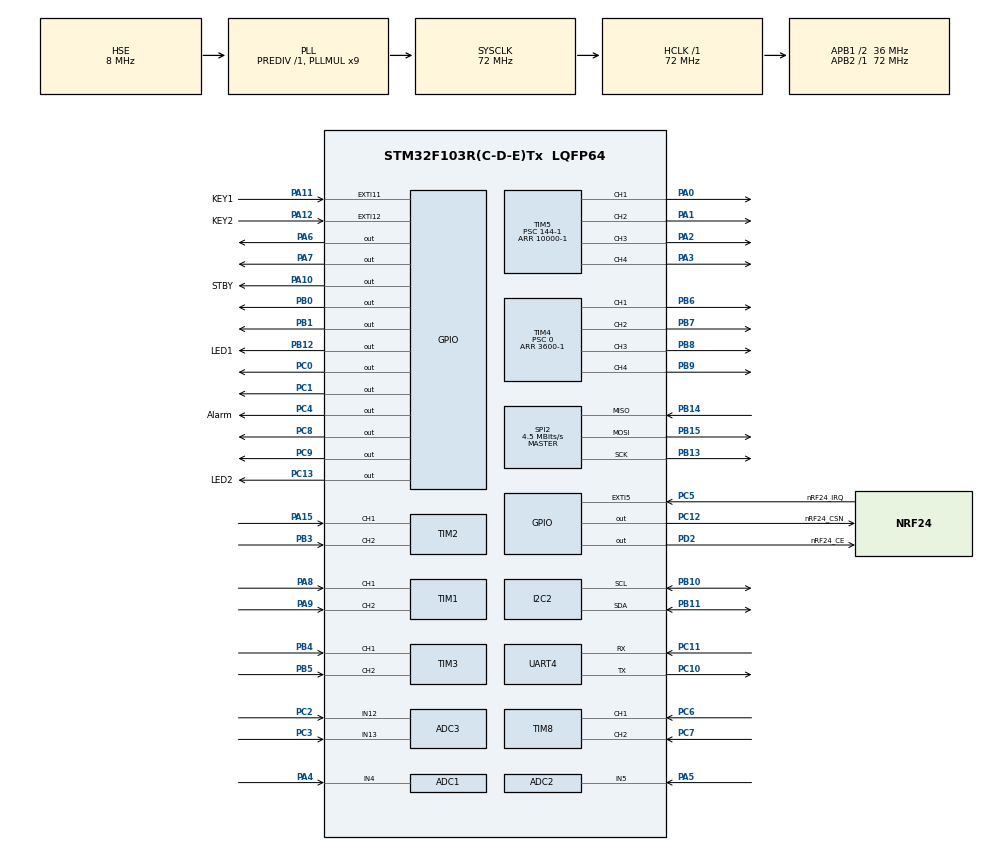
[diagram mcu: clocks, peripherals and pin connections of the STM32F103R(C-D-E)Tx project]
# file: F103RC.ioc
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ADC1.Channel-0\#ChannelRegularConversion=ADC_CHANNEL_4
ADC1.ContinuousConvMode=ENABLE
ADC1.EnableInjectedConversion=DISABLE
ADC1.Mode=ADC_DUALMODE_REGSIMULT
ADC1.NbrOfConversionFlag=1
ADC1.Rank-0\#ChannelRegularConversion=1
ADC1.SamplingTime-0\#ChannelRegularConversion=ADC_SAMPLETIME_55CYCLES_5
ADC1.master=1
ADC2.Channel-2\#ChannelRegularConversion=ADC_CHANNEL_5
ADC2.ContinuousConvMode=ENABLE
ADC2.Mode=ADC_DUALMODE_REGSIMULT
ADC2.NbrOfConversionFlag=1
ADC2.Rank-2\#ChannelRegularConversion=1
ADC2.SamplingTime-2\#ChannelRegularConversion=ADC_SAMPLETIME_55CYCLES_5
ADC3.Channel-0\#ChannelRegularConversion=ADC_CHANNEL_12
ADC3.Channel-1\#ChannelRegularConversion=ADC_CHANNEL_13
ADC3.NbrOfConversion=2
ADC3.NbrOfConversionFlag=1
ADC3.Rank-0\#ChannelRegularConversion=1
ADC3.Rank-1\#ChannelRegularConversion=2
ADC3.SamplingTime-0\#ChannelRegularConversion=ADC_SAMPLETIME_55CYCLES_5
ADC3.SamplingTime-1\#ChannelRegularConversion=ADC_SAMPLETIME_55CYCLES_5
Dma.ADC1.0.Direction=DMA_PERIPH_TO_MEMORY
Dma.ADC1.0.Instance=DMA1_Channel1
Dma.ADC1.0.MemDataAlignment=DMA_MDATAALIGN_WORD
Dma.ADC1.0.MemInc=DMA_MINC_ENABLE
Dma.ADC1.0.Mode=DMA_CIRCULAR
Dma.ADC1.0.PeriphDataAlignment=DMA_PDATAALIGN_WORD
Dma.ADC1.0.PeriphInc=DMA_PINC_DISABLE
Dma.ADC1.0.Priority=DMA_PRIORITY_LOW
Dma.Request0=ADC1
FREERTOS.INCLUDE_uxTaskGetStackHighWaterMark=1
FREERTOS.INCLUDE_vTaskDelayUntil=1
FREERTOS.Tasks01=App_Remote_Task,2,512,StartApp_Remote_Task,As weak,NULL,Dynamic,NULL,NULL;App_ChassisTask,1,1024,StartApp_Chassis_Task,As weak,NULL,Dynamic,NULL,NULL;App_Grab_Task,0,768,StartApp_Grab_Task,As weak,NULL,Dynamic,NULL,NULL;App_Sense_Task,-1,256,StartApp_Sense_Task,As weak,NULL,Dynamic,NULL,NULL;App_Daemon_Task,-2,768,StartApp_Daemon_Task,As weak,NULL,Dynamic,NULL,NULL;App_TestBench_T,0,512,StartApp_TestBench_Task,As weak,NULL,Dynamic,NULL,NULL
FREERTOS.configTOTAL_HEAP_SIZE=20480
Mcu.Family=STM32F1
Mcu.Name=STM32F103R(C-D-E)Tx
Mcu.Package=LQFP64
NVIC.DMA1_Channel1_IRQn=true\:5\:0\:false\:false\:true\:true\:false\:true\:true
NVIC.EXTI15_10_IRQn=true\:5\:0\:false\:false\:true\:true\:true\:true\:true
NVIC.EXTI9_5_IRQn=true\:5\:0\:false\:false\:true\:true\:true\:true\:true
NVIC.PriorityGroup=NVIC_PRIORITYGROUP_4
NVIC.TIM6_IRQn=true\:15\:0\:false\:false\:true\:false\:false\:true\:true
NVIC.TimeBase=TIM6_IRQn
NVIC.TimeBaseIP=TIM6
NVIC.UART4_IRQn=true\:5\:0\:false\:false\:true\:true\:true\:true\:true
PA0-WKUP.Signal=S_TIM5_CH1
PA1.Signal=S_TIM5_CH2
PA10.GPIO_Label=STBY
PA10.Signal=GPIO_Output
PA11.GPIO_Label=KEY1
PA11.GPIO_ModeDefaultEXTI=GPIO_MODE_IT_FALLING
PA11.GPIO_PuPd=GPIO_PULLUP
PA11.Signal=GPXTI11
PA12.GPIO_Label=KEY2
PA12.GPIO_ModeDefaultEXTI=GPIO_MODE_IT_FALLING
PA12.GPIO_PuPd=GPIO_PULLUP
PA12.Signal=GPXTI12
PA13.Mode=Serial_Wire
PA13.Signal=SYS_JTMS-SWDIO
PA14.Mode=Serial_Wire
PA14.Signal=SYS_JTCK-SWCLK
PA15.Signal=S_TIM2_CH1_ETR
PA2.Signal=S_TIM5_CH3
PA3.Signal=S_TIM5_CH4
PA4.Signal=ADCx_IN4
PA5.Signal=ADCx_IN5
PA6.Signal=GPIO_Output
PA7.Signal=GPIO_Output
PA8.Signal=S_TIM1_CH1
PA9.Signal=S_TIM1_CH2
PB0.Signal=GPIO_Output
PB1.Signal=GPIO_Output
PB10.Mode=I2C
PB10.Signal=I2C2_SCL
PB11.Mode=I2C
PB11.Signal=I2C2_SDA
PB12.GPIO_Label=LED1
PB12.Signal=GPIO_Output
PB13.Mode=Full_Duplex_Master
PB13.Signal=SPI2_SCK
PB14.Mode=Full_Duplex_Master
PB14.Signal=SPI2_MISO
PB15.Mode=Full_Duplex_Master
PB15.Signal=SPI2_MOSI
PB3.Signal=S_TIM2_CH2
PB4.Signal=S_TIM3_CH1
PB5.Signal=S_TIM3_CH2
PB6.Signal=S_TIM4_CH1
PB7.Signal=S_TIM4_CH2
PB8.Signal=S_TIM4_CH3
PB9.Signal=S_TIM4_CH4
PC0.Signal=GPIO_Output
PC1.Signal=GPIO_Output
PC10.Mode=Asynchronous
PC10.Signal=UART4_TX
PC11.Mode=Asynchronous
PC11.Signal=UART4_RX
PC12.GPIO_Label=nRF24_CSN
PC12.PinState=GPIO_PIN_SET
PC12.Signal=GPIO_Output
PC13-TAMPER-RTC.GPIO_Label=LED2
PC13-TAMPER-RTC.Signal=GPIO_Output
PC2.Signal=ADCx_IN12
PC3.Signal=ADCx_IN13
PC4.GPIO_Label=Alarm
PC4.Signal=GPIO_Output
PC5.GPIO_Label=nRF24_IRQ
PC5.GPIO_ModeDefaultEXTI=GPIO_MODE_IT_FALLING
PC5.GPIO_PuPd=GPIO_PULLUP
PC5.Signal=GPXTI5
PC6.Signal=S_TIM8_CH1
PC7.Signal=S_TIM8_CH2
PC8.Signal=GPIO_Output
PC9.Signal=GPIO_Output
PD0-OSC_IN.Mode=HSE-External-Oscillator
PD0-OSC_IN.Signal=RCC_OSC_IN
PD1-OSC_OUT.Mode=HSE-External-Oscillator
PD1-OSC_OUT.Signal=RCC_OSC_OUT
PD2.GPIO_Label=nRF24_CE
PD2.Signal=GPIO_Output
ProjectManager.HeapSize=0x200
ProjectManager.StackSize=0x400
ProjectManager.TargetToolchain=CMake
RCC.ADCPresc=RCC_ADCPCLK2_DIV6
RCC.AHBFreq_Value=72000000
RCC.APB1CLKDivider=RCC_HCLK_DIV2
RCC.APB1Freq_Value=36000000
RCC.APB1TimFreq_Value=72000000
RCC.APB2Freq_Value=72000000
RCC.APB2TimFreq_Value=72000000
RCC.HCLKFreq_Value=72000000
RCC.PLLMUL=RCC_PLL_MUL9
RCC.PLLSourceVirtual=RCC_PLLSOURCE_HSE
RCC.SYSCLKFreq_VALUE=72000000
RCC.SYSCLKSource=RCC_SYSCLKSOURCE_PLLCLK
RCC.USBFreq_Value=72000000
SH.ADCx_IN12.0=ADC3_IN12,IN12
SH.ADCx_IN13.0=ADC3_IN13,IN13
SH.ADCx_IN4.0=ADC1_IN4,IN4
SH.ADCx_IN5.0=ADC2_IN5,IN5
SH.S_TIM1_CH1.0=TIM1_CH1,Encoder_Interface
SH.S_TIM1_CH2.0=TIM1_CH2,Encoder_Interface
SH.S_TIM2_CH1_ETR.0=TIM2_CH1,Encoder_Interface
SH.S_TIM2_CH2.0=TIM2_CH2,Encoder_Interface
SH.S_TIM3_CH1.0=TIM3_CH1,Encoder_Interface
SH.S_TIM3_CH2.0=TIM3_CH2,Encoder_Interface
SH.S_TIM4_CH1.0=TIM4_CH1,PWM Generation1 CH1
SH.S_TIM4_CH2.0=TIM4_CH2,PWM Generation2 CH2
SH.S_TIM4_CH3.0=TIM4_CH3,PWM Generation3 CH3
SH.S_TIM4_CH4.0=TIM4_CH4,PWM Generation4 CH4
SH.S_TIM5_CH1.0=TIM5_CH1,PWM Generation1 CH1
SH.S_TIM5_CH2.0=TIM5_CH2,PWM Generation2 CH2
SH.S_TIM5_CH3.0=TIM5_CH3,PWM Generation3 CH3
SH.S_TIM5_CH4.0=TIM5_CH4,PWM Generation4 CH4
SH.S_TIM8_CH1.0=TIM8_CH1,Encoder_Interface
SH.S_TIM8_CH2.0=TIM8_CH2,Encoder_Interface
SPI2.BaudRatePrescaler=SPI_BAUDRATEPRESCALER_8
SPI2.CalculateBaudRate=4.5 MBits/s
SPI2.Direction=SPI_DIRECTION_2LINES
SPI2.Mode=SPI_MODE_MASTER
SPI2.VirtualType=VM_MASTER
TIM1.EncoderMode=TIM_ENCODERMODE_TI12
TIM1.IC1Filter=5
TIM1.IC2Filter=5
TIM2.EncoderMode=TIM_ENCODERMODE_TI12
TIM2.IC1Filter=5
TIM2.IC2Filter=5
TIM3.EncoderMode=TIM_ENCODERMODE_TI12
TIM3.IC1Filter=5
TIM3.IC2Filter=5
TIM4.Channel-PWM\ Generation1\ CH1=TIM_CHANNEL_1
TIM4.Channel-PWM\ Generation2\ CH2=TIM_CHANNEL_2
TIM4.Channel-PWM\ Generation3\ CH3=TIM_CHANNEL_3
TIM4.Channel-PWM\ Generation4\ CH4=TIM_CHANNEL_4
TIM4.Period=3600-1
TIM4.Prescaler=0
TIM5.Channel-PWM\ Generation1\ CH1=TIM_CHANNEL_1
TIM5.Channel-PWM\ Generation2\ CH2=TIM_CHANNEL_2
TIM5.Channel-PWM\ Generation3\ CH3=TIM_CHANNEL_3
TIM5.Channel-PWM\ Generation4\ CH4=TIM_CHANNEL_4
TIM5.Period=10000-1
TIM5.Prescaler=144-1
TIM8.EncoderMode=TIM_ENCODERMODE_TI12
TIM8.IC1Filter=5
TIM8.IC2Filter=5
UART4.VirtualMode=Asynchronous
VP_FREERTOS_VS_CMSIS_V1.Mode=CMSIS_V1
VP_SYS_VS_tim6.Mode=TIM6
VP_TIM4_VS_ClockSourceINT.Mode=Internal
board=custom

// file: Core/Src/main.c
/* USER CODE BEGIN Header */
/**
  ******************************************************************************
  * @file           : main.c
  * @brief          : Main program body
  ******************************************************************************
  * @attention
  *
  * Copyright (c) 2026 STMicroelectronics.
  * All rights reserved.
  *
  * This software is licensed under terms that can be found in the LICENSE file
  * in the root directory of this software component.
  * If no LICENSE file comes with this software, it is provided AS-IS.
  *
  ******************************************************************************
  */
/* USER CODE END Header */
#include "main.h"
#include "cmsis_os.h"
#include "adc.h"
#include "dma.h"
#include "i2c.h"
#include "spi.h"
#include "tim.h"
#include "usart.h"
#include "gpio.h"

/* USER CODE BEGIN Includes */
#include "bsp_sys.h"
#include "bsp_log.h"
#include "bsp_encoder.h"
#include "bsp_pwm.h"
#include "bsp_adc.h"
#include "bsp_iic.h"
/* USER CODE END Includes */

void SystemClock_Config(void);
void MX_FREERTOS_Init(void);

int main(void)
{

  /* MCU Configuration--------------------------------------------------------*/

  /* Reset of all peripherals, Initializes the Flash interface and the Systick. */
  HAL_Init();

  /* Configure the system clock */
  SystemClock_Config();

  /* Initialize all configured peripherals */
  MX_GPIO_Init();
  MX_DMA_Init();
  MX_ADC1_Init();
  MX_ADC2_Init();
  MX_ADC3_Init();
  MX_I2C2_Init();
  MX_SPI2_Init();
  MX_TIM1_Init();
  MX_TIM2_Init();
  MX_TIM3_Init();
  MX_TIM4_Init();
  MX_TIM5_Init();
  MX_TIM8_Init();
  MX_UART4_Init();
  /* USER CODE BEGIN 2 */
  /* ADC方案B: 双同步+连续转换+DMA循环由硬件自动搬运, 不需要DMA中断.
   * CubeMX在双同步模式下强制使能DMA1_Channel1中断(界面置灰不可关),
   * 在此显式屏蔽, 避免循环模式下半满/全满中断频繁打断RTOS任务. */
  HAL_NVIC_DisableIRQ(DMA1_Channel1_IRQn);
  /* S0: BSP 初始化（时钟自检 + DWT）与日志口启动（UART4 已在上面 MX 初始化） */
  Bsp_Init();
  Log_Init();
  /* S3: 启动四路编码器计数（MX_TIMx_Init 的编码器配置已在上面完成） */
  Encoder_InitAll();
  /* S4: 启动 8 路 PWM 输出（compare 保持 CubeMX Pulse=0：duty 0 / 不发脉冲） */
  Pwm_InitAll();
  /* S6: 启动 ADC1/2 双同步 DMA 循环采样（校准+丢前2窗）与 ADC3 单通道轮询配置 */
  Adc_Init();
  /* S7: I²C2 总线服务就绪（校验 hi2c2；阻塞读写+超时+总线恢复见 Iic_*） */
  Iic_Init();
  /* USER CODE END 2 */

  /* Call init function for freertos objects (in cmsis_os2.c) */
  MX_FREERTOS_Init();

  /* Start scheduler */
  osKernelStart();

  /* We should never get here as control is now taken by the scheduler */

  /* Infinite loop */
  while (1)
  {

  }
}

void SystemClock_Config(void)
{
  RCC_OscInitTypeDef RCC_OscInitStruct = {0};
  RCC_ClkInitTypeDef RCC_ClkInitStruct = {0};
  RCC_PeriphCLKInitTypeDef PeriphClkInit = {0};

  /** Initializes the RCC Oscillators according to the specified parameters
  * in the RCC_OscInitTypeDef structure.
  */
  RCC_OscInitStruct.OscillatorType = RCC_OSCILLATORTYPE_HSE;
  RCC_OscInitStruct.HSEState = RCC_HSE_ON;
  RCC_OscInitStruct.HSEPredivValue = RCC_HSE_PREDIV_DIV1;
  RCC_OscInitStruct.HSIState = RCC_HSI_ON;
  RCC_OscInitStruct.PLL.PLLState = RCC_PLL_ON;
  RCC_OscInitStruct.PLL.PLLSource = RCC_PLLSOURCE_HSE;
  RCC_OscInitStruct.PLL.PLLMUL = RCC_PLL_MUL9;
  if (HAL_RCC_OscConfig(&RCC_OscInitStruct) != HAL_OK)
  {
    Error_Handler();
  }

  /** Initializes the CPU, AHB and APB buses clocks
  */
  RCC_ClkInitStruct.ClockType = RCC_CLOCKTYPE_HCLK|RCC_CLOCKTYPE_SYSCLK
                              |RCC_CLOCKTYPE_PCLK1|RCC_CLOCKTYPE_PCLK2;
  RCC_ClkInitStruct.SYSCLKSource = RCC_SYSCLKSOURCE_PLLCLK;
  RCC_ClkInitStruct.AHBCLKDivider = RCC_SYSCLK_DIV1;
  RCC_ClkInitStruct.APB1CLKDivider = RCC_HCLK_DIV2;
  RCC_ClkInitStruct.APB2CLKDivider = RCC_HCLK_DIV1;

  if (HAL_RCC_ClockConfig(&RCC_ClkInitStruct, FLASH_LATENCY_2) != HAL_OK)
  {
    Error_Handler();
  }
  PeriphClkInit.PeriphClockSelection = RCC_PERIPHCLK_ADC;
  PeriphClkInit.AdcClockSelection = RCC_ADCPCLK2_DIV6;
  if (HAL_RCCEx_PeriphCLKConfig(&PeriphClkInit) != HAL_OK)
  {
    Error_Handler();
  }
}

void HAL_TIM_PeriodElapsedCallback(TIM_HandleTypeDef *htim)
{
  if (htim->Instance == TIM6)
  {
    HAL_IncTick();
  }
}

void Error_Handler(void)
{
  __disable_irq();
  while (1)
  {
  }
}

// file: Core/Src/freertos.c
/* USER CODE BEGIN Header */
/**
  ******************************************************************************
  * File Name          : freertos.c
  * Description        : Code for freertos applications
  ******************************************************************************
  * @attention
  *
  * Copyright (c) 2026 STMicroelectronics.
  * All rights reserved.
  *
  * This software is licensed under terms that can be found in the LICENSE file
  * in the root directory of this software component.
  * If no LICENSE file comes with this software, it is provided AS-IS.
  *
  ******************************************************************************
  */
/* USER CODE END Header */

#include "FreeRTOS.h"
#include "task.h"
#include "main.h"
#include "cmsis_os.h"

osThreadId App_Remote_TaskHandle;
osThreadId App_ChassisTaskHandle;
osThreadId App_Grab_TaskHandle;
osThreadId App_Sense_TaskHandle;
osThreadId App_Daemon_TaskHandle;
osThreadId App_TestBench_THandle;

void StartApp_Remote_Task(void const * argument);
void StartApp_Chassis_Task(void const * argument);
void StartApp_Grab_Task(void const * argument);
void StartApp_Sense_Task(void const * argument);
void StartApp_Daemon_Task(void const * argument);
void StartApp_TestBench_Task(void const * argument);

void MX_FREERTOS_Init(void); /* (MISRA C 2004 rule 8.1) */

/* GetIdleTaskMemory prototype (linked to static allocation support) */
void vApplicationGetIdleTaskMemory( StaticTask_t **ppxIdleTaskTCBBuffer, StackType_t **ppxIdleTaskStackBuffer, uint32_t *pulIdleTaskStackSize );

/* USER CODE BEGIN GET_IDLE_TASK_MEMORY */
static StaticTask_t xIdleTaskTCBBuffer;
static StackType_t xIdleStack[configMINIMAL_STACK_SIZE];

void vApplicationGetIdleTaskMemory( StaticTask_t **ppxIdleTaskTCBBuffer, StackType_t **ppxIdleTaskStackBuffer, uint32_t *pulIdleTaskStackSize )
{
  *ppxIdleTaskTCBBuffer = &xIdleTaskTCBBuffer;
  *ppxIdleTaskStackBuffer = &xIdleStack[0];
  *pulIdleTaskStackSize = configMINIMAL_STACK_SIZE;
  /* place for user code */
}
/* USER CODE END GET_IDLE_TASK_MEMORY */

void MX_FREERTOS_Init(void) {

  /* Create the thread(s) */
  /* definition and creation of App_Remote_Task */
  osThreadDef(App_Remote_Task, StartApp_Remote_Task, osPriorityHigh, 0, 512);
  App_Remote_TaskHandle = osThreadCreate(osThread(App_Remote_Task), NULL);

  /* definition and creation of App_ChassisTask */
  osThreadDef(App_ChassisTask, StartApp_Chassis_Task, osPriorityAboveNormal, 0, 1024);
  App_ChassisTaskHandle = osThreadCreate(osThread(App_ChassisTask), NULL);

  /* definition and creation of App_Grab_Task */
  osThreadDef(App_Grab_Task, StartApp_Grab_Task, osPriorityNormal, 0, 768);
  App_Grab_TaskHandle = osThreadCreate(osThread(App_Grab_Task), NULL);

  /* definition and creation of App_Sense_Task */
  osThreadDef(App_Sense_Task, StartApp_Sense_Task, osPriorityBelowNormal, 0, 256);
  App_Sense_TaskHandle = osThreadCreate(osThread(App_Sense_Task), NULL);

  /* definition and creation of App_Daemon_Task */
  osThreadDef(App_Daemon_Task, StartApp_Daemon_Task, osPriorityLow, 0, 768);
  App_Daemon_TaskHandle = osThreadCreate(osThread(App_Daemon_Task), NULL);

  /* definition and creation of App_TestBench_T */
  osThreadDef(App_TestBench_T, StartApp_TestBench_Task, osPriorityNormal, 0, 512);
  App_TestBench_THandle = osThreadCreate(osThread(App_TestBench_T), NULL);

}

__weak void StartApp_Remote_Task(void const * argument)
{
  for(;;)
  {
    osDelay(1);
  }
}

__weak void StartApp_Chassis_Task(void const * argument)
{
  for(;;)
  {
    osDelay(1);
  }
}

__weak void StartApp_Grab_Task(void const * argument)
{
  for(;;)
  {
    osDelay(1);
  }
}

__weak void StartApp_Sense_Task(void const * argument)
{
  for(;;)
  {
    osDelay(1);
  }
}

__weak void StartApp_Daemon_Task(void const * argument)
{
  for(;;)
  {
    osDelay(1);
  }
}

__weak void StartApp_TestBench_Task(void const * argument)
{
  for(;;)
  {
    osDelay(1);
  }
}
